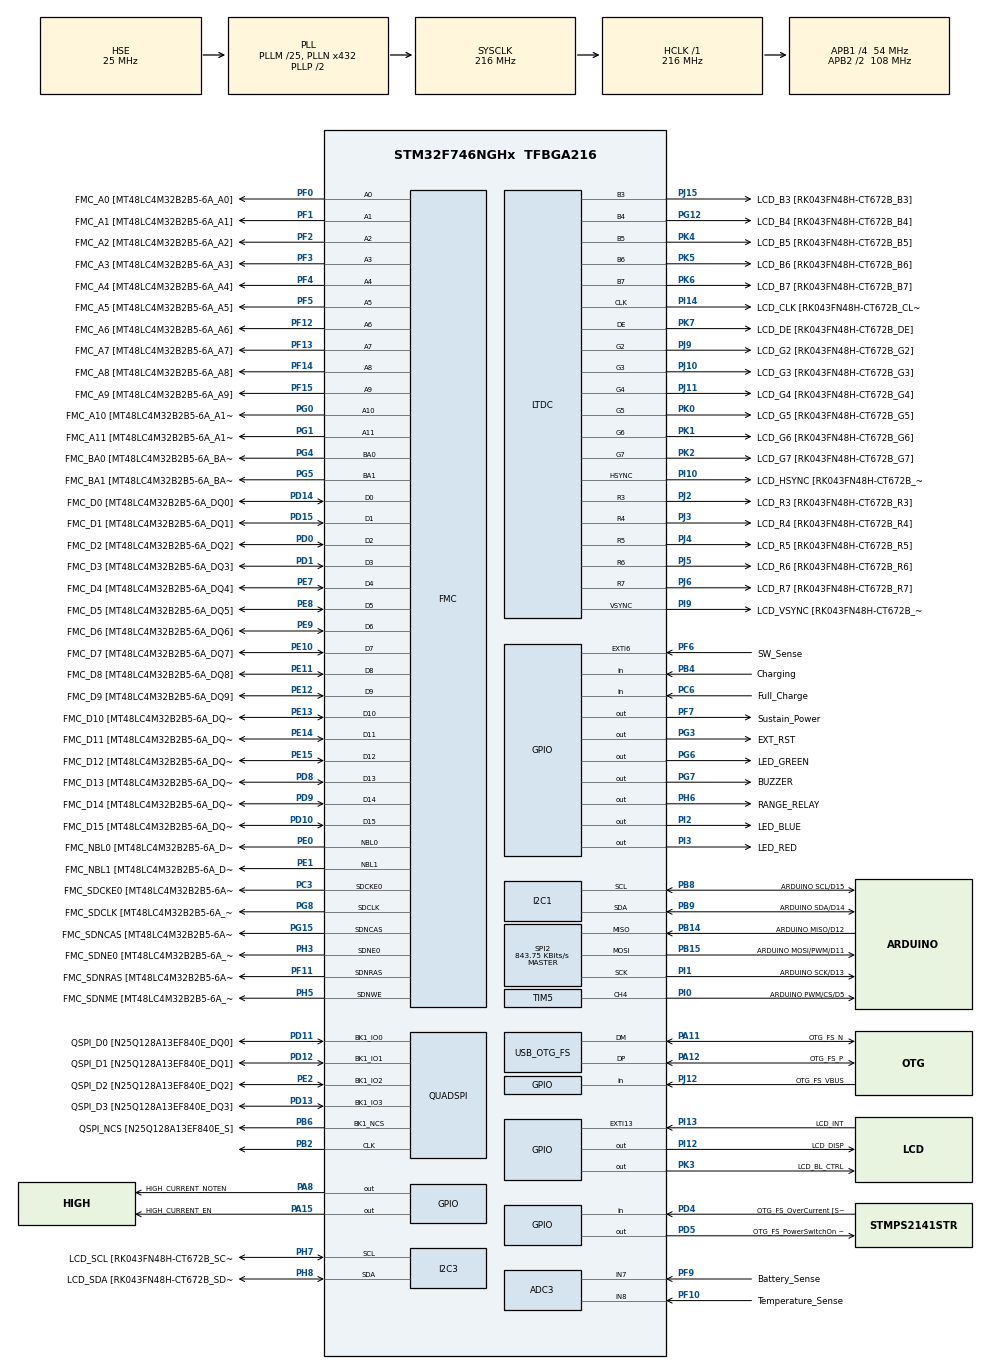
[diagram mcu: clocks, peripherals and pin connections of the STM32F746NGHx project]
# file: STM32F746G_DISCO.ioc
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ADC3.Channel-0\#ChannelRegularConversion=ADC_CHANNEL_7
ADC3.Channel-1\#ChannelRegularConversion=ADC_CHANNEL_8
ADC3.ContinuousConvMode=ENABLE
ADC3.DMAContinuousRequests=ENABLE
ADC3.ExternalTrigConv=ADC_EXTERNALTRIGCONV_T1_TRGO
ADC3.NbrOfConversion=2
ADC3.NbrOfConversionFlag=1
ADC3.Rank-0\#ChannelRegularConversion=1
ADC3.Rank-1\#ChannelRegularConversion=2
ADC3.SamplingTime-0\#ChannelRegularConversion=ADC_SAMPLETIME_480CYCLES
ADC3.SamplingTime-1\#ChannelRegularConversion=ADC_SAMPLETIME_480CYCLES
ADC3.ScanConvMode=ADC_SCAN_ENABLE
CORTEX_M7.ART_ACCLERATOR_ENABLE=1
CORTEX_M7.AccessPermission-Cortex_Memory_Protection_Unit_Region0_Settings=MPU_REGION_FULL_ACCESS
CORTEX_M7.AccessPermission-Cortex_Memory_Protection_Unit_Region1_Settings=MPU_REGION_FULL_ACCESS
CORTEX_M7.AccessPermission-Cortex_Memory_Protection_Unit_Region2_Settings=MPU_REGION_FULL_ACCESS
CORTEX_M7.AccessPermission-Cortex_Memory_Protection_Unit_Region3_Settings=MPU_REGION_FULL_ACCESS
CORTEX_M7.AccessPermission-Cortex_Memory_Protection_Unit_Region4_Settings=MPU_REGION_FULL_ACCESS
CORTEX_M7.AccessPermission-Cortex_Memory_Protection_Unit_Region5_Settings=MPU_REGION_FULL_ACCESS
CORTEX_M7.BaseAddress-Cortex_Memory_Protection_Unit_Region0_Settings=0x90000000
CORTEX_M7.BaseAddress-Cortex_Memory_Protection_Unit_Region1_Settings=0x90000000
CORTEX_M7.BaseAddress-Cortex_Memory_Protection_Unit_Region2_Settings=0xC0000000
CORTEX_M7.BaseAddress-Cortex_Memory_Protection_Unit_Region3_Settings=0x20000000
CORTEX_M7.BaseAddress-Cortex_Memory_Protection_Unit_Region4_Settings=0x8000000
CORTEX_M7.BaseAddress-Cortex_Memory_Protection_Unit_Region5_Settings=0x60000000
CORTEX_M7.CPU_DCache=Enabled
CORTEX_M7.CPU_ICache=Enabled
CORTEX_M7.Enable-Cortex_Memory_Protection_Unit_Region0_Settings=MPU_REGION_ENABLE
CORTEX_M7.Enable-Cortex_Memory_Protection_Unit_Region1_Settings=MPU_REGION_ENABLE
CORTEX_M7.Enable-Cortex_Memory_Protection_Unit_Region2_Settings=MPU_REGION_ENABLE
CORTEX_M7.Enable-Cortex_Memory_Protection_Unit_Region3_Settings=MPU_REGION_ENABLE
CORTEX_M7.Enable-Cortex_Memory_Protection_Unit_Region4_Settings=MPU_REGION_ENABLE
CORTEX_M7.Enable-Cortex_Memory_Protection_Unit_Region5_Settings=MPU_REGION_ENABLE
CORTEX_M7.IsBufferable-Cortex_Memory_Protection_Unit_Region2_Settings=MPU_ACCESS_BUFFERABLE
CORTEX_M7.IsCacheable-Cortex_Memory_Protection_Unit_Region1_Settings=MPU_ACCESS_CACHEABLE
CORTEX_M7.IsCacheable-Cortex_Memory_Protection_Unit_Region2_Settings=MPU_ACCESS_CACHEABLE
CORTEX_M7.IsCacheable-Cortex_Memory_Protection_Unit_Region3_Settings=MPU_ACCESS_CACHEABLE
CORTEX_M7.IsCacheable-Cortex_Memory_Protection_Unit_Region4_Settings=MPU_ACCESS_CACHEABLE
CORTEX_M7.IsCacheable-Cortex_Memory_Protection_Unit_Region5_Settings=MPU_ACCESS_CACHEABLE
CORTEX_M7.IsShareable-Cortex_Memory_Protection_Unit_Region2_Settings=MPU_ACCESS_SHAREABLE
CORTEX_M7.IsShareable-Cortex_Memory_Protection_Unit_Region3_Settings=MPU_ACCESS_SHAREABLE
CORTEX_M7.IsShareable-Cortex_Memory_Protection_Unit_Region5_Settings=MPU_ACCESS_SHAREABLE
CORTEX_M7.MPU_Control=MPU_HFNMI_PRIVDEF
CORTEX_M7.PREFETCH_ENABLE=1
CORTEX_M7.Size-Cortex_Memory_Protection_Unit_Region0_Settings=MPU_REGION_SIZE_256MB
CORTEX_M7.Size-Cortex_Memory_Protection_Unit_Region1_Settings=MPU_REGION_SIZE_16MB
CORTEX_M7.Size-Cortex_Memory_Protection_Unit_Region2_Settings=MPU_REGION_SIZE_8MB
CORTEX_M7.Size-Cortex_Memory_Protection_Unit_Region3_Settings=MPU_REGION_SIZE_8KB
CORTEX_M7.Size-Cortex_Memory_Protection_Unit_Region4_Settings=MPU_REGION_SIZE_1MB
CORTEX_M7.Size-Cortex_Memory_Protection_Unit_Region5_Settings=MPU_REGION_SIZE_512MB
CRC.InputDataFormat=CRC_INPUTDATA_FORMAT_WORDS
CRC.OutputDataInversionMode=CRC_OUTPUTDATA_INVERSION_ENABLE
DMA2D.ColorMode=DMA2D_OUTPUT_RGB565
DMA2D.Mode=DMA2D_R2M
Dma.ADC3.0.Direction=DMA_PERIPH_TO_MEMORY
Dma.ADC3.0.FIFOMode=DMA_FIFOMODE_DISABLE
Dma.ADC3.0.Instance=DMA2_Stream1
Dma.ADC3.0.MemDataAlignment=DMA_MDATAALIGN_HALFWORD
Dma.ADC3.0.MemInc=DMA_MINC_ENABLE
Dma.ADC3.0.Mode=DMA_CIRCULAR
Dma.ADC3.0.PeriphDataAlignment=DMA_PDATAALIGN_HALFWORD
Dma.ADC3.0.PeriphInc=DMA_PINC_DISABLE
Dma.ADC3.0.Priority=DMA_PRIORITY_LOW
Dma.Request0=ADC3
Dma.Request1=SPI2_RX
Dma.Request2=SPI2_TX
Dma.SPI2_RX.1.Direction=DMA_PERIPH_TO_MEMORY
Dma.SPI2_RX.1.FIFOMode=DMA_FIFOMODE_DISABLE
Dma.SPI2_RX.1.Instance=DMA1_Stream3
Dma.SPI2_RX.1.MemDataAlignment=DMA_MDATAALIGN_BYTE
Dma.SPI2_RX.1.MemInc=DMA_MINC_ENABLE
Dma.SPI2_RX.1.Mode=DMA_NORMAL
Dma.SPI2_RX.1.PeriphDataAlignment=DMA_PDATAALIGN_BYTE
Dma.SPI2_RX.1.PeriphInc=DMA_PINC_DISABLE
Dma.SPI2_RX.1.Priority=DMA_PRIORITY_LOW
Dma.SPI2_TX.2.Direction=DMA_MEMORY_TO_PERIPH
Dma.SPI2_TX.2.FIFOMode=DMA_FIFOMODE_DISABLE
Dma.SPI2_TX.2.Instance=DMA1_Stream4
Dma.SPI2_TX.2.MemDataAlignment=DMA_MDATAALIGN_BYTE
Dma.SPI2_TX.2.MemInc=DMA_MINC_ENABLE
Dma.SPI2_TX.2.Mode=DMA_NORMAL
Dma.SPI2_TX.2.PeriphDataAlignment=DMA_PDATAALIGN_BYTE
Dma.SPI2_TX.2.PeriphInc=DMA_PINC_DISABLE
Dma.SPI2_TX.2.Priority=DMA_PRIORITY_LOW
FMC.CASLatency1=FMC_SDRAM_CAS_LATENCY_3
FMC.ExitSelfRefreshDelay1=6
FMC.LoadToActiveDelay1=2
FMC.RCDDelay1=2
FMC.RPDelay1=2
FMC.RPDelay2=2
FMC.ReadBurst1=FMC_SDRAM_RBURST_ENABLE
FMC.ReadBurst2=FMC_SDRAM_RBURST_ENABLE
FMC.ReadPipeDelay1=FMC_SDRAM_RPIPE_DELAY_2
FMC.ReadPipeDelay2=FMC_SDRAM_RPIPE_DELAY_2
FMC.RowCycleDelay1=6
FMC.RowCycleDelay2=6
FMC.SDClockPeriod1=FMC_SDRAM_CLOCK_PERIOD_3
FMC.SDClockPeriod2=FMC_SDRAM_CLOCK_PERIOD_3
FMC.SelfRefreshTime1=4
FMC.WriteRecoveryTime1=2
FREERTOS.HEAP_NUMBER=4
FREERTOS.INCLUDE_eTaskGetState=0
FREERTOS.INCLUDE_uxTaskGetStackHighWaterMark=1
FREERTOS.INCLUDE_vTaskDelayUntil=1
FREERTOS.INCLUDE_xQueueGetMutexHolder=1
FREERTOS.MEMORY_ALLOCATION=2
FREERTOS.Tasks01=defaultTaskHand,8,4096,StartDefaultTask,Default,NULL,Dynamic,NULL,NULL
FREERTOS.configCHECK_FOR_STACK_OVERFLOW=0
FREERTOS.configENABLE_FPU=1
FREERTOS.configMAX_TASK_NAME_LEN=25
FREERTOS.configTICK_RATE_HZ=1000
FREERTOS.configTOTAL_HEAP_SIZE=32768
FREERTOS.configUSE_APPLICATION_TASK_TAG=1
FREERTOS.configUSE_COUNTING_SEMAPHORES=1
FREERTOS.configUSE_CO_ROUTINES=1
FREERTOS.configUSE_IDLE_HOOK=0
FREERTOS.configUSE_MALLOC_FAILED_HOOK=0
FREERTOS.configUSE_RECURSIVE_MUTEXES=1
FREERTOS.configUSE_TICK_HOOK=0
I2C1.Timing=0x20404768
I2C3.I2C_Rise_Time=0
I2C3.Speed=100
I2C3.Timing=0x20404768
LTDC.ActiveH=272
LTDC.ActiveW=480
LTDC.Alpha_L0=255
LTDC.BlendingFactor1_L0=LTDC_BLENDING_FACTOR1_CA
LTDC.BlendingFactor2_L0=LTDC_BLENDING_FACTOR2_CA
LTDC.FBStartAdress_L0=0xC0000000
LTDC.Green_L0=0
LTDC.HBP=13
LTDC.HFP=32
LTDC.HSync=41
LTDC.ImageHeight_L0=272
LTDC.ImageWidth_L0=480
LTDC.Layers=0
LTDC.PixelFormat_L0=LTDC_PIXEL_FORMAT_RGB565
LTDC.VSync=10
LTDC.WindowX1_L0=480
LTDC.WindowY1_L0=272
Mcu.Family=STM32F7
Mcu.Name=STM32F746NGHx
Mcu.Package=TFBGA216
NVIC.DMA1_Stream3_IRQn=true\:5\:0\:false\:false\:true\:false\:false\:true\:true
NVIC.DMA1_Stream4_IRQn=true\:5\:0\:false\:false\:true\:false\:false\:true\:true
NVIC.DMA2D_IRQn=true\:15\:0\:true\:false\:true\:true\:true\:true\:true
NVIC.DMA2_Stream1_IRQn=true\:14\:0\:true\:false\:true\:true\:false\:true\:true
NVIC.EXTI9_5_IRQn=true\:10\:0\:true\:false\:true\:false\:true\:true\:true
NVIC.I2C1_ER_IRQn=true\:12\:0\:true\:false\:true\:true\:true\:true\:true
NVIC.I2C1_EV_IRQn=true\:12\:0\:true\:false\:true\:true\:true\:true\:true
NVIC.LTDC_ER_IRQn=true\:15\:0\:true\:false\:true\:true\:true\:true\:true
NVIC.LTDC_IRQn=true\:15\:0\:true\:false\:true\:true\:true\:true\:true
NVIC.OTG_FS_IRQn=true\:15\:0\:true\:false\:true\:true\:true\:true\:true
NVIC.PriorityGroup=NVIC_PRIORITYGROUP_4
NVIC.TIM1_TRG_COM_TIM11_IRQn=true\:15\:0\:true\:false\:true\:false\:false\:true\:true
NVIC.TIM3_IRQn=true\:3\:0\:true\:false\:true\:false\:true\:true\:true
NVIC.TIM5_IRQn=true\:3\:0\:true\:false\:true\:false\:true\:true\:true
NVIC.TIM7_IRQn=true\:13\:0\:true\:false\:true\:false\:true\:true\:true
NVIC.TIM8_CC_IRQn=true\:3\:0\:true\:false\:true\:false\:true\:true\:true
NVIC.TimeBase=TIM1_TRG_COM_TIM11_IRQn
NVIC.TimeBaseIP=TIM11
PA0/WKUP.GPIO_Label=WakeUpPin
PA0/WKUP.Mode=SYS_WakeUp0
PA0/WKUP.Signal=SYS_WKUP1
PA11.GPIO_Label=OTG_FS_N
PA11.Mode=Device_Only
PA11.Signal=USB_OTG_FS_DM
PA12.GPIO_Label=OTG_FS_P
PA12.Mode=Device_Only
PA12.Signal=USB_OTG_FS_DP
PA13.GPIO_Label=SWDIO
PA13.Mode=Serial_Wire
PA13.Signal=SYS_JTMS-SWDIO
PA14.GPIO_Label=SWCLK
PA14.Mode=Serial_Wire
PA14.Signal=SYS_JTCK-SWCLK
PA15.GPIO_Label=HIGH_CURRENT_EN
PA15.GPIO_PuPd=GPIO_PULLDOWN
PA15.GPIO_Speed=GPIO_SPEED_FREQ_VERY_HIGH
PA15.Signal=GPIO_Output
PA8.GPIO_Label=HIGH_CURRENT_NOTEN
PA8.GPIO_PuPd=GPIO_PULLUP
PA8.GPIO_Speed=GPIO_SPEED_FREQ_VERY_HIGH
PA8.PinState=GPIO_PIN_SET
PA8.Signal=GPIO_Output
PB14.GPIO_Label=ARDUINO MISO/D12
PB14.GPIO_Mode=GPIO_MODE_AF_PP
PB14.GPIO_PuPd=GPIO_NOPULL
PB14.GPIO_Speed=GPIO_SPEED_FREQ_VERY_HIGH
PB14.Mode=Full_Duplex_Master
PB14.Signal=SPI2_MISO
PB15.GPIO_Label=ARDUINO MOSI/PWM/D11
PB15.GPIO_Mode=GPIO_MODE_AF_PP
PB15.GPIO_PuPd=GPIO_NOPULL
PB15.GPIO_Speed=GPIO_SPEED_FREQ_VERY_HIGH
PB15.Mode=Full_Duplex_Master
PB15.Signal=SPI2_MOSI
PB2.Mode=Single Bank 1
PB2.Signal=QUADSPI_CLK
PB3.Signal=SYS_JTDO-SWO
PB4.GPIO_Label=Charging
PB4.GPIO_PuPd=GPIO_PULLDOWN
PB4.Signal=GPIO_Input
PB6.GPIO_Label=QSPI_NCS [N25Q128A13EF840E_S]
PB6.Mode=Single Bank 1
PB6.Signal=QUADSPI_BK1_NCS
PB8.GPIO_Label=ARDUINO SCL/D15
PB8.GPIO_Mode=GPIO_MODE_AF_OD
PB8.GPIO_Pu=GPIO_PULLUP
PB8.GPIO_PuPd=GPIO_NOPULL
PB8.GPIO_Speed=GPIO_SPEED_FREQ_LOW
PB8.Mode=I2C
PB8.Signal=I2C1_SCL
PB9.GPIO_Label=ARDUINO SDA/D14
PB9.GPIO_Mode=GPIO_MODE_AF_OD
PB9.GPIO_Pu=GPIO_PULLUP
PB9.GPIO_PuPd=GPIO_NOPULL
PB9.GPIO_Speed=GPIO_SPEED_FREQ_LOW
PB9.Mode=I2C
PB9.Signal=I2C1_SDA
PC3.GPIO_Label=FMC_SDCKE0 [MT48LC4M32B2B5-6A_CKE]
PC3.Mode=SdramChipSelect1_1
PC3.Signal=FMC_SDCKE0
PC6.GPIO_Label=Full_Charge
PC6.GPIO_PuPd=GPIO_PULLUP
PC6.Signal=GPIO_Input
PD0.GPIO_Label=FMC_D2 [MT48LC4M32B2B5-6A_DQ2]
PD0.Signal=FMC_D2_DA2
PD1.GPIO_Label=FMC_D3 [MT48LC4M32B2B5-6A_DQ3]
PD1.Signal=FMC_D3_DA3
PD10.GPIO_Label=FMC_D15 [MT48LC4M32B2B5-6A_DQ15]
PD10.Signal=FMC_D15_DA15
PD11.GPIO_Label=QSPI_D0 [N25Q128A13EF840E_DQ0]
PD11.Mode=Single Bank 1
PD11.Signal=QUADSPI_BK1_IO0
PD12.GPIO_Label=QSPI_D1 [N25Q128A13EF840E_DQ1]
PD12.Mode=Single Bank 1
PD12.Signal=QUADSPI_BK1_IO1
PD13.GPIO_Label=QSPI_D3 [N25Q128A13EF840E_DQ3]
PD13.Mode=Single Bank 1
PD13.Signal=QUADSPI_BK1_IO3
PD14.GPIO_Label=FMC_D0 [MT48LC4M32B2B5-6A_DQ0]
PD14.Signal=FMC_D0_DA0
PD15.GPIO_Label=FMC_D1 [MT48LC4M32B2B5-6A_DQ1]
PD15.Signal=FMC_D1_DA1
PD4.GPIO_Label=OTG_FS_OverCurrent [STMPS2141STR_Fault]
PD4.Signal=GPIO_Input
PD5.GPIO_Label=OTG_FS_PowerSwitchOn [STMPS2141STR_EN]
PD5.GPIO_Speed=GPIO_SPEED_FREQ_HIGH
PD5.PinState=GPIO_PIN_SET
PD5.Signal=GPIO_Output
PD8.GPIO_Label=FMC_D13 [MT48LC4M32B2B5-6A_DQ13]
PD8.Signal=FMC_D13_DA13
PD9.GPIO_Label=FMC_D14 [MT48LC4M32B2B5-6A_DQ14]
PD9.Signal=FMC_D14_DA14
PE0.GPIO_Label=FMC_NBL0 [MT48LC4M32B2B5-6A_DQM0]
PE0.Signal=FMC_NBL0
PE1.GPIO_Label=FMC_NBL1 [MT48LC4M32B2B5-6A_DQM1]
PE1.Signal=FMC_NBL1
PE10.GPIO_Label=FMC_D7 [MT48LC4M32B2B5-6A_DQ7]
PE10.Signal=FMC_D7_DA7
PE11.GPIO_Label=FMC_D8 [MT48LC4M32B2B5-6A_DQ8]
PE11.Signal=FMC_D8_DA8
PE12.GPIO_Label=FMC_D9 [MT48LC4M32B2B5-6A_DQ9]
PE12.Signal=FMC_D9_DA9
PE13.GPIO_Label=FMC_D10 [MT48LC4M32B2B5-6A_DQ10]
PE13.Signal=FMC_D10_DA10
PE14.GPIO_Label=FMC_D11 [MT48LC4M32B2B5-6A_DQ11]
PE14.Signal=FMC_D11_DA11
PE15.GPIO_Label=FMC_D12 [MT48LC4M32B2B5-6A_DQ12]
PE15.Signal=FMC_D12_DA12
PE2.GPIO_Label=QSPI_D2 [N25Q128A13EF840E_DQ2]
PE2.Mode=Single Bank 1
PE2.Signal=QUADSPI_BK1_IO2
PE7.GPIO_Label=FMC_D4 [MT48LC4M32B2B5-6A_DQ4]
PE7.Signal=FMC_D4_DA4
PE8.GPIO_Label=FMC_D5 [MT48LC4M32B2B5-6A_DQ5]
PE8.Signal=FMC_D5_DA5
PE9.GPIO_Label=FMC_D6 [MT48LC4M32B2B5-6A_DQ6]
PE9.Signal=FMC_D6_DA6
PF0.GPIO_Label=FMC_A0 [MT48LC4M32B2B5-6A_A0]
PF0.Signal=FMC_A0
PF1.GPIO_Label=FMC_A1 [MT48LC4M32B2B5-6A_A1]
PF1.Signal=FMC_A1
PF10.GPIO_Label=Temperature_Sense
PF10.GPIO_Mode=GPIO_MODE_ANALOG
PF10.GPIO_PuPd=GPIO_NOPULL
PF10.Mode=IN8
PF10.Signal=ADC3_IN8
PF11.GPIO_Label=FMC_SDNRAS [MT48LC4M32B2B5-6A_RAS]
PF11.Signal=FMC_SDNRAS
PF12.GPIO_Label=FMC_A6 [MT48LC4M32B2B5-6A_A6]
PF12.Signal=FMC_A6
PF13.GPIO_Label=FMC_A7 [MT48LC4M32B2B5-6A_A7]
PF13.Signal=FMC_A7
PF14.GPIO_Label=FMC_A8 [MT48LC4M32B2B5-6A_A8]
PF14.Signal=FMC_A8
PF15.GPIO_Label=FMC_A9 [MT48LC4M32B2B5-6A_A9]
PF15.Signal=FMC_A9
PF2.GPIO_Label=FMC_A2 [MT48LC4M32B2B5-6A_A2]
PF2.Signal=FMC_A2
PF3.GPIO_Label=FMC_A3 [MT48LC4M32B2B5-6A_A3]
PF3.Signal=FMC_A3
PF4.GPIO_Label=FMC_A4 [MT48LC4M32B2B5-6A_A4]
PF4.Signal=FMC_A4
PF5.GPIO_Label=FMC_A5 [MT48LC4M32B2B5-6A_A5]
PF5.Signal=FMC_A5
PF6.GPIO_Label=SW_Sense
PF6.GPIO_ModeDefaultEXTI=GPIO_MODE_IT_RISING
PF6.GPIO_PuPd=GPIO_NOPULL
PF6.Signal=GPXTI6
PF7.GPIO_Label=Sustain_Power
PF7.GPIO_PuPd=GPIO_PULLDOWN
PF7.GPIO_Speed=GPIO_SPEED_FREQ_HIGH
PF7.PinState=GPIO_PIN_SET
PF7.Signal=GPIO_Output
PF9.GPIO_Label=Battery_Sense
PF9.GPIO_Mode=GPIO_MODE_ANALOG
PF9.GPIO_PuPd=GPIO_NOPULL
PF9.Mode=IN7
PF9.Signal=ADC3_IN7
PG0.GPIO_Label=FMC_A10 [MT48LC4M32B2B5-6A_A10]
PG0.Signal=FMC_A10
PG1.GPIO_Label=FMC_A11 [MT48LC4M32B2B5-6A_A11]
PG1.Signal=FMC_A11
PG12.GPIO_Label=LCD_B4 [RK043FN48H-CT672B_B4]
PG12.GPIO_Speed=GPIO_SPEED_FREQ_VERY_HIGH
PG12.Mode=RGB565
PG12.Signal=LTDC_B4
PG15.GPIO_Label=FMC_SDNCAS [MT48LC4M32B2B5-6A_CAS]
PG15.Signal=FMC_SDNCAS
PG3.GPIO_Label=EXT_RST
PG3.Signal=GPIO_Output
PG4.GPIO_Label=FMC_BA0 [MT48LC4M32B2B5-6A_BA0]
PG4.Signal=FMC_A14_BA0
PG5.GPIO_Label=FMC_BA1 [MT48LC4M32B2B5-6A_BA1]
PG5.Signal=FMC_A15_BA1
PG6.GPIO_Label=LED_GREEN
PG6.PinState=GPIO_PIN_SET
PG6.Signal=GPIO_Output
PG7.GPIO_Label=BUZZER
PG7.GPIO_PuPd=GPIO_PULLUP
PG7.GPIO_Speed=GPIO_SPEED_FREQ_HIGH
PG7.Signal=GPIO_Output
PG8.GPIO_Label=FMC_SDCLK [MT48LC4M32B2B5-6A_CLK]
PG8.Signal=FMC_SDCLK
PH0/OSC_IN.GPIO_Label=OSC_25M [NZ2520SB-25.00M_OUT]
PH0/OSC_IN.Mode=HSE-External-Oscillator
PH0/OSC_IN.Signal=RCC_OSC_IN
PH1/OSC_OUT.Mode=HSE-External-Oscillator
PH1/OSC_OUT.Signal=RCC_OSC_OUT
PH3.GPIO_Label=FMC_SDNE0 [MT48LC4M32B2B5-6A_CS]
PH3.Mode=SdramChipSelect1_1
PH3.Signal=FMC_SDNE0
PH5.GPIO_Label=FMC_SDNME [MT48LC4M32B2B5-6A_WE]
PH5.Signal=FMC_SDNWE
PH6.GPIO_Label=RANGE_RELAY
PH6.GPIO_Speed=GPIO_SPEED_FREQ_HIGH
PH6.Signal=GPIO_Output
PH7.GPIO_Label=LCD_SCL [RK043FN48H-CT672B_SCL]
PH7.GPIO_Pu=GPIO_PULLUP
PH7.Mode=I2C
PH7.Signal=I2C3_SCL
PH8.GPIO_Label=LCD_SDA [RK043FN48H-CT672B_SDA]
PH8.GPIO_Pu=GPIO_PULLUP
PH8.Mode=I2C
PH8.Signal=I2C3_SDA
PI0.GPIO_Label=ARDUINO PWM/CS/D5
PI0.GPIO_ModeDefaultPP=GPIO_MODE_AF_PP
PI0.GPIO_PuPd=GPIO_NOPULL
PI0.GPIO_Speed=GPIO_SPEED_FREQ_LOW
PI0.Signal=S_TIM5_CH4
PI1.GPIO_Label=ARDUINO SCK/D13
PI1.GPIO_Mode=GPIO_MODE_AF_PP
PI1.GPIO_PuPd=GPIO_NOPULL
PI1.GPIO_Speed=GPIO_SPEED_FREQ_VERY_HIGH
PI1.Mode=Full_Duplex_Master
PI1.Signal=SPI2_SCK
PI10.GPIO_Label=LCD_HSYNC [RK043FN48H-CT672B_HSYNC]
PI10.GPIO_Speed=GPIO_SPEED_FREQ_VERY_HIGH
PI10.Mode=RGB565
PI10.Signal=LTDC_HSYNC
PI12.GPIO_Label=LCD_DISP
PI12.PinState=GPIO_PIN_SET
PI12.Signal=GPIO_Output
PI13.GPIO_Label=LCD_INT
PI13.GPIO_ModeDefaultEXTI=GPIO_MODE_EVT_RISING
PI13.Signal=GPXTI13
PI14.GPIO_Label=LCD_CLK [RK043FN48H-CT672B_CLK]
PI14.GPIO_Speed=GPIO_SPEED_FREQ_VERY_HIGH
PI14.Mode=RGB565
PI14.Signal=LTDC_CLK
PI2.GPIO_Label=LED_BLUE
PI2.GPIO_Speed=GPIO_SPEED_FREQ_HIGH
PI2.PinState=GPIO_PIN_SET
PI2.Signal=GPIO_Output
PI3.GPIO_Label=LED_RED
PI3.GPIO_Speed=GPIO_SPEED_FREQ_HIGH
PI3.PinState=GPIO_PIN_SET
PI3.Signal=GPIO_Output
PI9.GPIO_Label=LCD_VSYNC [RK043FN48H-CT672B_VSYNC]
PI9.GPIO_Speed=GPIO_SPEED_FREQ_VERY_HIGH
PI9.Mode=RGB565
PI9.Signal=LTDC_VSYNC
PJ10.GPIO_Label=LCD_G3 [RK043FN48H-CT672B_G3]
PJ10.GPIO_Speed=GPIO_SPEED_FREQ_VERY_HIGH
PJ10.Mode=RGB565
PJ10.Signal=LTDC_G3
PJ11.GPIO_Label=LCD_G4 [RK043FN48H-CT672B_G4]
PJ11.GPIO_Speed=GPIO_SPEED_FREQ_VERY_HIGH
PJ11.Mode=RGB565
PJ11.Signal=LTDC_G4
PJ12.GPIO_Label=OTG_FS_VBUS
PJ12.Signal=GPIO_Input
PJ15.GPIO_Label=LCD_B3 [RK043FN48H-CT672B_B3]
PJ15.GPIO_Speed=GPIO_SPEED_FREQ_VERY_HIGH
PJ15.Mode=RGB565
PJ15.Signal=LTDC_B3
PJ2.GPIO_Label=LCD_R3 [RK043FN48H-CT672B_R3]
PJ2.GPIO_Speed=GPIO_SPEED_FREQ_VERY_HIGH
PJ2.Mode=RGB565
PJ2.Signal=LTDC_R3
PJ3.GPIO_Label=LCD_R4 [RK043FN48H-CT672B_R4]
PJ3.GPIO_Speed=GPIO_SPEED_FREQ_VERY_HIGH
PJ3.Mode=RGB565
PJ3.Signal=LTDC_R4
PJ4.GPIO_Label=LCD_R5 [RK043FN48H-CT672B_R5]
PJ4.GPIO_Speed=GPIO_SPEED_FREQ_VERY_HIGH
PJ4.Mode=RGB565
PJ4.Signal=LTDC_R5
PJ5.GPIO_Label=LCD_R6 [RK043FN48H-CT672B_R6]
PJ5.GPIO_Speed=GPIO_SPEED_FREQ_VERY_HIGH
PJ5.Mode=RGB565
PJ5.Signal=LTDC_R6
PJ6.GPIO_Label=LCD_R7 [RK043FN48H-CT672B_R7]
PJ6.GPIO_Speed=GPIO_SPEED_FREQ_VERY_HIGH
PJ6.Mode=RGB565
PJ6.Signal=LTDC_R7
PJ9.GPIO_Label=LCD_G2 [RK043FN48H-CT672B_G2]
PJ9.GPIO_Speed=GPIO_SPEED_FREQ_VERY_HIGH
PJ9.Mode=RGB565
PJ9.Signal=LTDC_G2
PK0.GPIO_Label=LCD_G5 [RK043FN48H-CT672B_G5]
PK0.GPIO_Speed=GPIO_SPEED_FREQ_VERY_HIGH
PK0.Mode=RGB565
PK0.Signal=LTDC_G5
PK1.GPIO_Label=LCD_G6 [RK043FN48H-CT672B_G6]
PK1.GPIO_Speed=GPIO_SPEED_FREQ_VERY_HIGH
PK1.Mode=RGB565
PK1.Signal=LTDC_G6
PK2.GPIO_Label=LCD_G7 [RK043FN48H-CT672B_G7]
PK2.GPIO_Speed=GPIO_SPEED_FREQ_VERY_HIGH
PK2.Mode=RGB565
PK2.Signal=LTDC_G7
PK3.GPIO_Label=LCD_BL_CTRL
PK3.GPIO_Speed=GPIO_SPEED_FREQ_LOW
PK3.PinState=GPIO_PIN_SET
PK3.Signal=GPIO_Output
PK4.GPIO_Label=LCD_B5 [RK043FN48H-CT672B_B5]
PK4.GPIO_Speed=GPIO_SPEED_FREQ_VERY_HIGH
PK4.Mode=RGB565
PK4.Signal=LTDC_B5
PK5.GPIO_Label=LCD_B6 [RK043FN48H-CT672B_B6]
PK5.GPIO_Speed=GPIO_SPEED_FREQ_VERY_HIGH
PK5.Mode=RGB565
PK5.Signal=LTDC_B6
PK6.GPIO_Label=LCD_B7 [RK043FN48H-CT672B_B7]
PK6.GPIO_Speed=GPIO_SPEED_FREQ_VERY_HIGH
PK6.Mode=RGB565
PK6.Signal=LTDC_B7
PK7.GPIO_Label=LCD_DE [RK043FN48H-CT672B_DE]
PK7.GPIO_Speed=GPIO_SPEED_FREQ_VERY_HIGH
PK7.Mode=RGB565
PK7.Signal=LTDC_DE
ProjectManager.HeapSize=0xF00
ProjectManager.StackSize=0xF00
ProjectManager.TargetToolchain=MDK-ARM V5.32
QUADSPI.ChipSelectHighTime=QSPI_CS_HIGH_TIME_6_CYCLE
QUADSPI.ClockPrescaler=1
QUADSPI.FifoThreshold=4
QUADSPI.FlashSize=24
QUADSPI.SampleShifting=QSPI_SAMPLE_SHIFTING_HALFCYCLE
RCC.AHBFreq_Value=216000000
RCC.APB1CLKDivider=RCC_HCLK_DIV4
RCC.APB1Freq_Value=54000000
RCC.APB1TimFreq_Value=108000000
RCC.APB2CLKDivider=RCC_HCLK_DIV2
RCC.APB2Freq_Value=108000000
RCC.APB2TimFreq_Value=216000000
RCC.CortexFreq_Value=216000000
RCC.EnbaleCSS=true
RCC.HCLKFreq_Value=216000000
RCC.HSE_VALUE=25000000
RCC.HSI_VALUE=16000000
RCC.LSE_VALUE=32768
RCC.PLLI2SN=100
RCC.PLLM=25
RCC.PLLN=432
RCC.PLLQ=9
RCC.PLLSAIN=100
RCC.PLLSAIP=RCC_PLLSAIP_DIV8
RCC.PLLSAIR=5
RCC.SDMMCClockSelection=RCC_SDMMC1CLKSOURCE_CLK48
RCC.SYSCLKFreq_VALUE=216000000
RCC.SYSCLKSource=RCC_SYSCLKSOURCE_PLLCLK
RCC.USBFreq_Value=48000000
RCC.VCOOutputFreq_Value=432000000
SH.FMC_A0.0=FMC_A0,12b-sda1
SH.FMC_A1.0=FMC_A1,12b-sda1
SH.FMC_A10.0=FMC_A10,12b-sda1
SH.FMC_A11.0=FMC_A11,12b-sda1
SH.FMC_A14_BA0.0=FMC_BA0,FourSdramBanks1
SH.FMC_A15_BA1.0=FMC_BA1,FourSdramBanks1
SH.FMC_A2.0=FMC_A2,12b-sda1
SH.FMC_A3.0=FMC_A3,12b-sda1
SH.FMC_A4.0=FMC_A4,12b-sda1
SH.FMC_A5.0=FMC_A5,12b-sda1
SH.FMC_A6.0=FMC_A6,12b-sda1
SH.FMC_A7.0=FMC_A7,12b-sda1
SH.FMC_A8.0=FMC_A8,12b-sda1
SH.FMC_A9.0=FMC_A9,12b-sda1
SH.FMC_D0_DA0.0=FMC_D0,sd-16b-d1
SH.FMC_D10_DA10.0=FMC_D10,sd-16b-d1
SH.FMC_D11_DA11.0=FMC_D11,sd-16b-d1
SH.FMC_D12_DA12.0=FMC_D12,sd-16b-d1
SH.FMC_D13_DA13.0=FMC_D13,sd-16b-d1
SH.FMC_D14_DA14.0=FMC_D14,sd-16b-d1
SH.FMC_D15_DA15.0=FMC_D15,sd-16b-d1
SH.FMC_D1_DA1.0=FMC_D1,sd-16b-d1
SH.FMC_D2_DA2.0=FMC_D2,sd-16b-d1
SH.FMC_D3_DA3.0=FMC_D3,sd-16b-d1
SH.FMC_D4_DA4.0=FMC_D4,sd-16b-d1
SH.FMC_D5_DA5.0=FMC_D5,sd-16b-d1
SH.FMC_D6_DA6.0=FMC_D6,sd-16b-d1
SH.FMC_D7_DA7.0=FMC_D7,sd-16b-d1
SH.FMC_D8_DA8.0=FMC_D8,sd-16b-d1
SH.FMC_D9_DA9.0=FMC_D9,sd-16b-d1
SH.FMC_NBL0.0=FMC_NBL0,Sd2ByteEnable1
SH.FMC_NBL1.0=FMC_NBL1,Sd2ByteEnable1
SH.FMC_SDCLK.0=FMC_SDCLK,12b-sda1
SH.FMC_SDNCAS.0=FMC_SDNCAS,12b-sda1
SH.FMC_SDNRAS.0=FMC_SDNRAS,12b-sda1
SH.FMC_SDNWE.0=FMC_SDNWE,12b-sda1
SH.S_TIM5_CH4.0=TIM5_CH4,PWM Generation4 CH4
SPI2.BaudRatePrescaler=SPI_BAUDRATEPRESCALER_64
SPI2.CalculateBaudRate=843.75 KBits/s
SPI2.DataSize=SPI_DATASIZE_8BIT
SPI2.Direction=SPI_DIRECTION_2LINES
SPI2.Mode=SPI_MODE_MASTER
SPI2.VirtualType=VM_MASTER
STMicroelectronics.X-CUBE-TOUCHGFX.4.17.0.ApplicationCcGraphicsJjApplication=TouchGFXOoGenerator
STMicroelectronics.X-CUBE-TOUCHGFX.4.17.0.tgfx_address1=0xC0000000
STMicroelectronics.X-CUBE-TOUCHGFX.4.17.0.tgfx_address2=0xC003FC00
STMicroelectronics.X-CUBE-TOUCHGFX.4.17.0.tgfx_buffering_strategy=Double
STMicroelectronics.X-CUBE-TOUCHGFX.4.17.0.tgfx_display_interface=disp_ltdc
STMicroelectronics.X-CUBE-TOUCHGFX.4.17.0.tgfx_hardware_accelerator=dma_2d
STMicroelectronics.X-CUBE-TOUCHGFX.4.17.0.tgfx_location=By Address
STMicroelectronics.X-CUBE-TOUCHGFX.4.17.0.tgfx_vsync=vsync_ltdc
STMicroelectronics.X-CUBE-TOUCHGFX.4.17.0_IsPackSelfContextualization=true
TIM1.Period=999
TIM1.Prescaler=21599
TIM1.TIM_MasterOutputTrigger=TIM_TRGO_UPDATE
TIM3.Period=20000 - 1
TIM3.Prescaler=2700 - 1
TIM5.Channel-PWM\ Generation3\ No\ Output=TIM_CHANNEL_3
TIM5.Channel-PWM\ Generation4\ CH4=TIM_CHANNEL_4
TIM5.Period=TIM5_Period
TIM5.Prescaler=TIM5_Prescaler
TIM5.Pulse-PWM\ Generation3\ No\ Output=TIM5_Pulse
TIM5.Pulse-PWM\ Generation4\ CH4=TIM5_Pulse
TIM7.Period=62
TIM7.Prescaler=5399
TIM8.Channel-Output\ Compare1\ No\ Output=TIM_CHANNEL_1
TIM8.Channel-Output\ Compare2\ No\ Output=TIM_CHANNEL_2
TIM8.Period=65535
TIM8.Prescaler=10799
TIM8.TIM_MasterOutputTrigger=TIM_TRGO_UPDATE
USB_DEVICE.APP_RX_DATA_SIZE-CDC_FS=RX_DATA_SIZE
USB_DEVICE.APP_TX_DATA_SIZE-CDC_FS=USB_TRANSMIT_SIZE
USB_DEVICE.CLASS_NAME_FS=CDC
USB_DEVICE.CLASS_NAME_HS=CDC
USB_DEVICE.PRODUCT_STRING_CDC_HS=STM32 DISCOVERY Virtual ComPort
USB_DEVICE.VirtualMode-CDC_FS=Cdc
USB_DEVICE.VirtualMode-CDC_HS=Cdc
USB_DEVICE.VirtualModeFS=Cdc_FS
USB_DEVICE.VirtualModeHS=Cdc_HS
USB_OTG_FS.VirtualMode=Device_Only
VP_CRC_VS_CRC.Mode=CRC_Activate
VP_DMA2D_VS_DMA2D.Mode=DMA2D_Activate
VP_FREERTOS_VS_CMSIS_V2.Mode=CMSIS_V2
VP_STMicroelectronics.X-CUBE-TOUCHGFX_VS_GraphicsJjApplication_4.17.0.Mode=GraphicsJjApplication
VP_SYS_VS_tim11.Mode=TIM11
VP_TIM1_VS_ClockSourceINT.Mode=Internal
VP_TIM3_VS_ClockSourceINT.Mode=Internal
VP_TIM5_VS_ClockSourceINT.Mode=Internal
VP_TIM5_VS_no_output3.Mode=PWM Generation3 No Output
VP_TIM7_VS_ClockSourceINT.Mode=Enable_Timer
VP_TIM8_VS_ClockSourceINT.Mode=Internal
VP_TIM8_VS_no_output1.Mode=Output Compare1 No Output
VP_TIM8_VS_no_output2.Mode=Output Compare2 No Output
VP_USB_DEVICE_VS_USB_DEVICE_CDC_FS.Mode=CDC_FS
board=32F746GDISCOVERY

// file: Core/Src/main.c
/* USER CODE BEGIN Header */
/**
  ******************************************************************************
  * @file           : main.c
  * @brief          : Main program body
  ******************************************************************************
  * @attention
  *
  * <h2><center>&copy; Copyright (c) 2019 STMicroelectronics.
  * All rights reserved.</center></h2>
  *
  * This software component is licensed by ST under Ultimate Liberty license
  * SLA0044, the "License"; You may not use this file except in compliance with
  * the License. You may obtain a copy of the License at:
  *                             www.st.com/SLA0044
  *
  ******************************************************************************
  */
	/* Timers Functionality:
	Timer 1: internal adc trigger
	Timer 3:
	Timer 5:
		channel 3 --> capture and index counter
		channel 4 -->
	Timer 7:
	*/
/* USER CODE END Header */
#include "main.h"
#include "cmsis_os.h"
#include "app_touchgfx.h"

/* USER CODE BEGIN Includes */
#include "usb_device.h"
/* USER CODE END Includes */

void SystemClock_Config(void);
static void MPU_Config(void);
void MX_FREERTOS_Init(void);

int main(void)
{

  /* USER CODE BEGIN 1 */
	//FPU----------------
	SCB->CPACR |= ((3UL << 10*2)|(3UL << 11*2));
  /* USER CODE END 1 */

  /* MPU Configuration--------------------------------------------------------*/
  MPU_Config();

  /* Enable the CPU Cache */

  /* Enable I-Cache---------------------------------------------------------*/
  SCB_EnableICache();

  /* Enable D-Cache---------------------------------------------------------*/
  SCB_EnableDCache();

  /* MCU Configuration--------------------------------------------------------*/

  /* Reset of all peripherals, Initializes the Flash interface and the Systick. */
  HAL_Init();

  /* USER CODE BEGIN Init */
//	Save_Device_ID(20, 10);
  /* USER CODE END Init */

  /* Configure the system clock */
  SystemClock_Config();

  /* USER CODE BEGIN SysInit */
  MX_GPIO_Init();
  MX_DMA_Init();
  MX_CRC_Init();
  MX_QUADSPI_Init();
	BSP_QSPI_Init();
  BSP_QSPI_MemoryMappedMode();
  HAL_NVIC_DisableIRQ(QUADSPI_IRQn);
  MX_DMA2D_Init();

  MX_FMC_Init();
	BSP_SDRAM_Initialization_sequence();
	Erase_Graphic_Buffers();
  MX_LTDC_Init();
  MX_I2C3_Init();

	HAL_Delay(50); // allow FT5336 to boot

	// FT5336 7-bit address is 0x38 -> 8-bit left-shifted
	for (int i = 0; i < 10; ++i) {
			if (HAL_I2C_IsDeviceReady(&hi2c3, (0x38 << 1), 1, 10) == HAL_OK) break;
			HAL_Delay(10);
	}
	MX_I2C1_Init();
  MX_TIM3_Init();
  MX_TIM5_Init();
  MX_TIM8_Init();
	MX_TIM1_Init();
	MX_TIM7_Init();
  MX_ADC3_Init();
  MX_SPI2_Init();

  /* USER CODE END SysInit */

  /* Initialize all configured peripherals */
  /* USER CODE BEGIN 2 */
	Go_to_High_Range();

	// Read First Conversion Value (This is necessary because the conversion will not proceed until the conversion data is read)
	Read_ADC_24Bit();

//	Erase_All_Projects_On_Flash();
//	Force_RecordNum0_And_ProjectNum1();
//	App_InitLatestInfo();

	Configure_and_Start_Timers();

	Initialize_RTC();

	HAL_GPIO_WritePin(LED_BLUE_GPIO_Port, LED_BLUE_Pin, GPIO_PIN_RESET);

	HAL_ADC_Start_DMA(&hadc3,(uint32_t*)ADC_ConvertedValue,2);

  /* USER CODE END 2 */

  /* Init scheduler */
  osKernelInitialize();  /* Call init function for freertos objects (in cmsis_os2.c) */
  MX_FREERTOS_Init();

  /* Start scheduler */
  osKernelStart();

  /* We should never get here as control is now taken by the scheduler */

  /* Infinite loop */
  while (1)
  {

    /* USER CODE BEGIN 3 */
//		HAL_GPIO_TogglePin(LED_RED_GPIO_Port,LED_RED_Pin);
//		HAL_Delay(500);
  }
  /* USER CODE END 3 */
}

void SystemClock_Config(void)
{
  RCC_OscInitTypeDef RCC_OscInitStruct = {0};
  RCC_ClkInitTypeDef RCC_ClkInitStruct = {0};

  /** Configure the main internal regulator output voltage
  */
  __HAL_RCC_PWR_CLK_ENABLE();
  __HAL_PWR_VOLTAGESCALING_CONFIG(PWR_REGULATOR_VOLTAGE_SCALE1);

  /** Initializes the RCC Oscillators according to the specified parameters
  * in the RCC_OscInitTypeDef structure.
  */
  RCC_OscInitStruct.OscillatorType = RCC_OSCILLATORTYPE_HSE;
  RCC_OscInitStruct.HSEState = RCC_HSE_ON;
  RCC_OscInitStruct.PLL.PLLState = RCC_PLL_ON;
  RCC_OscInitStruct.PLL.PLLSource = RCC_PLLSOURCE_HSE;
  RCC_OscInitStruct.PLL.PLLM = 25;
  RCC_OscInitStruct.PLL.PLLN = 432;
  RCC_OscInitStruct.PLL.PLLP = RCC_PLLP_DIV2;
  RCC_OscInitStruct.PLL.PLLQ = 9;
  if (HAL_RCC_OscConfig(&RCC_OscInitStruct) != HAL_OK)
  {
    Error_Handler();
  }

  /** Activate the Over-Drive mode
  */
  if (HAL_PWREx_EnableOverDrive() != HAL_OK)
  {
    Error_Handler();
  }

  /** Initializes the CPU, AHB and APB buses clocks
  */
  RCC_ClkInitStruct.ClockType = RCC_CLOCKTYPE_HCLK|RCC_CLOCKTYPE_SYSCLK
                              |RCC_CLOCKTYPE_PCLK1|RCC_CLOCKTYPE_PCLK2;
  RCC_ClkInitStruct.SYSCLKSource = RCC_SYSCLKSOURCE_PLLCLK;
  RCC_ClkInitStruct.AHBCLKDivider = RCC_SYSCLK_DIV1;
  RCC_ClkInitStruct.APB1CLKDivider = RCC_HCLK_DIV4;
  RCC_ClkInitStruct.APB2CLKDivider = RCC_HCLK_DIV2;

  if (HAL_RCC_ClockConfig(&RCC_ClkInitStruct, FLASH_LATENCY_7) != HAL_OK)
  {
    Error_Handler();
  }

  /** Enables the Clock Security System
  */
  HAL_RCC_EnableCSS();
}

/* USER CODE BEGIN 4 */
void Delay(uint32_t time)
{
	uint32_t n = 30265 * time;
	while(n > 0)
	{
		n--;
	}
}

/* USER CODE END 4 */

 /* MPU Configuration */

void MPU_Config(void)
{
  MPU_Region_InitTypeDef MPU_InitStruct = {0};

  /* Disables the MPU */
  HAL_MPU_Disable();

  /** Initializes and configures the Region and the memory to be protected
  */
  MPU_InitStruct.Enable = MPU_REGION_ENABLE;
  MPU_InitStruct.Number = MPU_REGION_NUMBER0;
  MPU_InitStruct.BaseAddress = 0x90000000;
  MPU_InitStruct.Size = MPU_REGION_SIZE_256MB;
  MPU_InitStruct.SubRegionDisable = 0x0;
  MPU_InitStruct.TypeExtField = MPU_TEX_LEVEL0;
  MPU_InitStruct.AccessPermission = MPU_REGION_FULL_ACCESS;
  MPU_InitStruct.DisableExec = MPU_INSTRUCTION_ACCESS_ENABLE;
  MPU_InitStruct.IsShareable = MPU_ACCESS_NOT_SHAREABLE;
  MPU_InitStruct.IsCacheable = MPU_ACCESS_NOT_CACHEABLE;
  MPU_InitStruct.IsBufferable = MPU_ACCESS_NOT_BUFFERABLE;

  HAL_MPU_ConfigRegion(&MPU_InitStruct);

  /** Initializes and configures the Region and the memory to be protected
  */
  MPU_InitStruct.Number = MPU_REGION_NUMBER1;
  MPU_InitStruct.Size = MPU_REGION_SIZE_16MB;
  MPU_InitStruct.IsCacheable = MPU_ACCESS_CACHEABLE;

  HAL_MPU_ConfigRegion(&MPU_InitStruct);

  /** Initializes and configures the Region and the memory to be protected
  */
  MPU_InitStruct.Number = MPU_REGION_NUMBER2;
  MPU_InitStruct.BaseAddress = 0xC0000000;
  MPU_InitStruct.Size = MPU_REGION_SIZE_8MB;
  MPU_InitStruct.IsShareable = MPU_ACCESS_SHAREABLE;
  MPU_InitStruct.IsBufferable = MPU_ACCESS_BUFFERABLE;

  HAL_MPU_ConfigRegion(&MPU_InitStruct);

  /** Initializes and configures the Region and the memory to be protected
  */
  MPU_InitStruct.Number = MPU_REGION_NUMBER3;
  MPU_InitStruct.BaseAddress = 0x20000000;
  MPU_InitStruct.Size = MPU_REGION_SIZE_8KB;
  MPU_InitStruct.IsBufferable = MPU_ACCESS_NOT_BUFFERABLE;

  HAL_MPU_ConfigRegion(&MPU_InitStruct);

  /** Initializes and configures the Region and the memory to be protected
  */
  MPU_InitStruct.Number = MPU_REGION_NUMBER4;
  MPU_InitStruct.BaseAddress = 0x8000000;
  MPU_InitStruct.Size = MPU_REGION_SIZE_1MB;
  MPU_InitStruct.IsShareable = MPU_ACCESS_NOT_SHAREABLE;

  HAL_MPU_ConfigRegion(&MPU_InitStruct);

  /** Initializes and configures the Region and the memory to be protected
  */
  MPU_InitStruct.Number = MPU_REGION_NUMBER5;
  MPU_InitStruct.BaseAddress = 0x60000000;
  MPU_InitStruct.Size = MPU_REGION_SIZE_512MB;
  MPU_InitStruct.IsShareable = MPU_ACCESS_SHAREABLE;

  HAL_MPU_ConfigRegion(&MPU_InitStruct);
  /* Enables the MPU */
  HAL_MPU_Enable(MPU_HFNMI_PRIVDEF);

}

void HAL_TIM_PeriodElapsedCallback(TIM_HandleTypeDef *htim)
{
  if (htim->Instance == TIM11)
  {
    HAL_IncTick();
  }
  /* USER CODE BEGIN Callback 1 */
	if (htim->Instance == TIM3) {
    TIMER3_Update_Interrupt_Handler(); // 1 second period
  }
	if (htim->Instance == TIM7)
	{
		UpdateAlarm(); // 32 Hz
		Sending_Request_to_RTC();
		Check_USB_Connection();
	}
  /* USER CODE END Callback 1 */
}

void Error_Handler(void)
{
}

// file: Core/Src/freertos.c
/* USER CODE BEGIN Header */
/**
  ******************************************************************************
  * File Name          : freertos.c
  * Description        : Code for freertos applications
  ******************************************************************************
  * @attention
  *
  * <h2><center>&copy; Copyright (c) 2019 STMicroelectronics.
  * All rights reserved.</center></h2>
  *
  * This software component is licensed by ST under Ultimate Liberty license
  * SLA0044, the "License"; You may not use this file except in compliance with
  * the License. You may obtain a copy of the License at:
  *                             www.st.com/SLA0044
  *
  ******************************************************************************
  */
/* USER CODE END Header */

#include "FreeRTOS.h"
#include "task.h"
#include "main.h"
#include "cmsis_os.h"

/* USER CODE BEGIN Includes */
#include "app_touchgfx.h"
/* USER CODE END Includes */

/* Definitions for defaultTaskHand */
osThreadId_t defaultTaskHandHandle;
const osThreadAttr_t defaultTaskHand_attributes = {
  .name = "defaultTaskHand",
  .stack_size = 4096 * 4,
  .priority = (osPriority_t) osPriorityLow,
};

/* USER CODE BEGIN FunctionPrototypes */
extern void MX_USB_DEVICE_Init(void);

/* USER CODE END FunctionPrototypes */

void StartDefaultTask(void *argument);

void MX_FREERTOS_Init(void); /* (MISRA C 2004 rule 8.1) */

void MX_FREERTOS_Init(void) {

  /* USER CODE BEGIN RTOS_TIMERS */
  /* start timers, add new ones, ... */
//	osTimerStart(TestTimerHandle, 100);

  /* USER CODE END RTOS_TIMERS */

  /* Create the thread(s) */
  /* creation of defaultTaskHand */
  defaultTaskHandHandle = osThreadNew(StartDefaultTask, NULL, &defaultTaskHand_attributes);

}

void StartDefaultTask(void *argument)
{
  /* USER CODE BEGIN StartDefaultTask */
	MX_TouchGFX_Init();

	MX_USB_DEVICE_Init();
	/* Initialize all configured peripherals */
	MX_TouchGFX_Process();
  /* Infinite loop */
  for(;;)
  {

    osDelay(1);
  }
  /* USER CODE END StartDefaultTask */
}
